# MSS_CPSW register map
Vendor: Texas Instruments
Peripheral module from a debugger description file (folder awr29xx).
Registers are 32-bit, read-write, no defined reset value unless marked. A register's access mark holds for its fields unless they carry their own. Offsets are as the file gives them; lines under a group give offsets from that group; [hi:lo] are bit positions; {n}, {i} and the like mark numbered series; 'fields as' and 'values as' point back to an identical list; <NAME> marks a mode.

## MSS_CPSW (part 1 of 3)
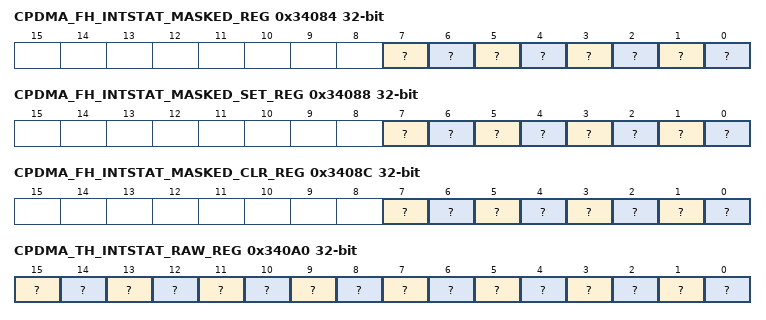
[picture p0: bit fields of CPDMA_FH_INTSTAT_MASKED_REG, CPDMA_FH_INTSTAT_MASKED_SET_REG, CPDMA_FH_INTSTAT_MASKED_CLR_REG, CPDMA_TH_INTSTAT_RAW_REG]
0x34084 CPDMA_FH_INTSTAT_MASKED_REG ro — CPDMA FHost Interrupt Status MASKED
  [7] ? — CPDMA FHost Channel 7 Interrupt Pending MASKED
  [6] ? — CPDMA FHost Channel 6 Interrupt Pending MASKED
  [5] ? — CPDMA FHost Channel 5 Interrupt Pending MASKED
  [4] ? — CPDMA FHost Channel 4 Interrupt Pending MASKED
  [3] ? — CPDMA FHost Channel 3 Interrupt Pending MASKED
  [2] ? — CPDMA FHost Channel 2 Interrupt Pending MASKED
  [1] ? — CPDMA FHost Channel 1 Interrupt Pending MASKED
  [0] ? — CPDMA FHost Channel 0 Interrupt Pending MASKED
0x34088 CPDMA_FH_INTSTAT_MASKED_SET_REG — CPDMA FHost Interrupt Masked SET
  [7] ? — CPDMA FHost Channel 7 Interrupt Pending MASKED Set
  [6] ? — CPDMA FHost Channel 6 Interrupt Pending MASKED Set
  [5] ? — CPDMA FHost Channel 5 Interrupt Pending MASKED Set
  [4] ? — CPDMA FHost Channel 4 Interrupt Pending MASKED Set
  [3] ? — CPDMA FHost Channel 3 Interrupt Pending MASKED Set
  [2] ? — CPDMA FHost Channel 2 Interrupt Pending MASKED Set
  [1] ? — CPDMA FHost Channel 1 Interrupt Pending MASKED Set
  [0] ? — CPDMA FHost Channel 0 Interrupt Pending MASKED Set
0x3408C CPDMA_FH_INTSTAT_MASKED_CLR_REG — CPDMA FHost Interrupt Masked CLR
  [7] ? — CPDMA FHost Channel 7 Interrupt Pending MASKED Clr
  [6] ? — CPDMA FHost Channel 6 Interrupt Pending MASKED Clr
  [5] ? — CPDMA FHost Channel 5 Interrupt Pending MASKED Clr
  [4] ? — CPDMA FHost Channel 4 Interrupt Pending MASKED Clr
  [3] ? — CPDMA FHost Channel 3 Interrupt Pending MASKED Clr
  [2] ? — CPDMA FHost Channel 2 Interrupt Pending MASKED Clr
  [1] ? — CPDMA FHost Channel 1 Interrupt Pending MASKED Clr
  [0] ? — CPDMA FHost Channel 0 Interrupt Pending MASKED Clr
0x34090 CPDMA_IN_VECTOR_REG ro — CPDMA DMA IN Vector
  [31:0] ?
0x34094 CPDMA_EOI_VECTOR_REG — CPDMA DMA EOI Vector
  [4:0] ?
0x340A0 CPDMA_TH_INTSTAT_RAW_REG ro — CPDMA Receive Interrupt Status RAW
  [15] ? — CPDMA Receive Channel 7 Threshold Interrupt Pending RAW
  [14] ? — CPDMA Receive Channel 6 Threshold Interrupt Pending RAW
  [13] ? — CPDMA Receive Channel 5 Threshold Interrupt Pending RAW
  [12] ? — CPDMA Receive Channel 4 Threshold Interrupt Pending RAW
  [11] ? — CPDMA Receive Channel 3 Threshold Interrupt Pending RAW
  [10] ? — CPDMA Receive Channel 2 Threshold Interrupt Pending RAW
  [9] ? — CPDMA Receive Channel 1 Threshold Interrupt Pending RAW
  [8] ? — CPDMA Receive Channel 0 Threshold Interrupt Pending RAW
  [7] ? — CPDMA Receive Channel 7 Interrupt Pending RAW
  [6] ? — CPDMA Receive Channel 6 Interrupt Pending RAW
  [5] ? — CPDMA Receive Channel 5 Interrupt Pending RAW
  [4] ? — CPDMA Receive Channel 4 Interrupt Pending RAW
  [3] ? — CPDMA Receive Channel 3 Interrupt Pending RAW
  [2] ? — CPDMA Receive Channel 2 Interrupt Pending RAW
  [1] ? — CPDMA Receive Channel 1 Interrupt Pending RAW
  [0] ? — CPDMA Receive Channel 0 Interrupt Pending RAW
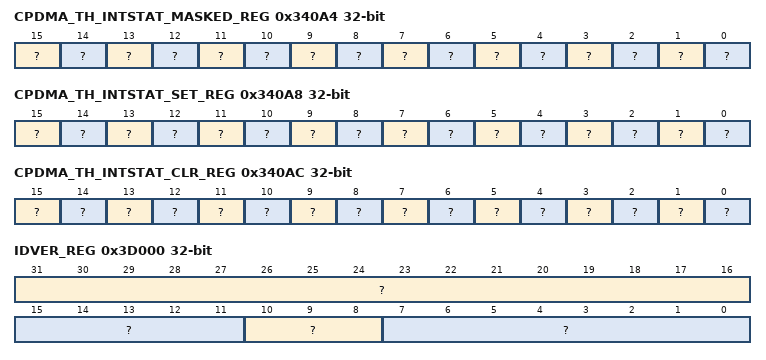
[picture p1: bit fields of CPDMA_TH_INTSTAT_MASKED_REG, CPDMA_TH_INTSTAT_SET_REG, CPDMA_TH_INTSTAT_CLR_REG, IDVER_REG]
0x340A4 CPDMA_TH_INTSTAT_MASKED_REG ro — CPDMA Receive Interrupt Status MASKED
  [15] ? — CPDMA Receive Channel 7 Threshold Interrupt Pending MASKED
  [14] ? — CPDMA Receive Channel 6 Threshold Interrupt Pending MASKED
  [13] ? — CPDMA Receive Channel 5 Threshold Interrupt Pending MASKED
  [12] ? — CPDMA Receive Channel 4 Threshold Interrupt Pending MASKED
  [11] ? — CPDMA Receive Channel 3 Threshold Interrupt Pending MASKED
  [10] ? — CPDMA Receive Channel 2 Threshold Interrupt Pending MASKED
  [9] ? — CPDMA Receive Channel 1 Threshold Interrupt Pending MASKED
  [8] ? — CPDMA Receive Channel 0 Threshold Interrupt Pending MASKED
  [7] ? — CPDMA Receive Channel 7 Interrupt Pending MASKED
  [6] ? — CPDMA Receive Channel 6 Interrupt Pending MASKED
  [5] ? — CPDMA Receive Channel 5 Interrupt Pending MASKED
  [4] ? — CPDMA Receive Channel 4 Interrupt Pending MASKED
  [3] ? — CPDMA Receive Channel 3 Interrupt Pending MASKED
  [2] ? — CPDMA Receive Channel 2 Interrupt Pending MASKED
  [1] ? — CPDMA Receive Channel 1 Interrupt Pending MASKED
  [0] ? — CPDMA Receive Channel 0 Interrupt Pending MASKED
0x340A8 CPDMA_TH_INTSTAT_SET_REG — CPDMA THost Interrupt Masked SET
  [15] ? — CPDMA THost Channel 7 Threshold Interrupt Pending SET
  [14] ? — CPDMA THost Channel 6 Threshold Interrupt Pending SET
  [13] ? — CPDMA THost Channel 5 Threshold Interrupt Pending SET
  [12] ? — CPDMA THost Channel 4 Threshold Interrupt Pending SET
  [11] ? — CPDMA THost Channel 3 Threshold Interrupt Pending SET
  [10] ? — CPDMA THost Channel 2 Threshold Interrupt Pending SET
  [9] ? — CPDMA THost Channel 1 Threshold Interrupt Pending SET
  [8] ? — CPDMA THost Channel 0 Threshold Interrupt Pending SET
  [7] ? — CPDMA THost Channel 7 Interrupt Pending SET
  [6] ? — CPDMA THost Channel 6 Interrupt Pending SET
  [5] ? — CPDMA THost Channel 5 Interrupt Pending SET
  [4] ? — CPDMA THost Channel 4 Interrupt Pending SET
  [3] ? — CPDMA THost Channel 3 Interrupt Pending SET
  [2] ? — CPDMA THost Channel 2 Interrupt Pending SET
  [1] ? — CPDMA THost Channel 1 Interrupt Pending SET
  [0] ? — CPDMA THost Channel 0 Interrupt Pending SET
0x340AC CPDMA_TH_INTSTAT_CLR_REG — CPDMA THost Interrupt Masked CLR
  [15] ? — CPDMA THost Channel 7 Threshold Interrupt Pending CLR
  [14] ? — CPDMA THost Channel 6 Threshold Interrupt Pending CLR
  [13] ? — CPDMA THost Channel 5 Threshold Interrupt Pending CLR
  [12] ? — CPDMA THost Channel 4 Threshold Interrupt Pending CLR
  [11] ? — CPDMA THost Channel 3 Threshold Interrupt Pending CLR
  [10] ? — CPDMA THost Channel 2 Threshold Interrupt Pending CLR
  [9] ? — CPDMA THost Channel 1 Threshold Interrupt Pending CLR
  [8] ? — CPDMA THost Channel 0 Threshold Interrupt Pending CLR
  [7] ? — CPDMA THost Channel 7 Interrupt Pending CLR
  [6] ? — CPDMA THost Channel 6 Interrupt Pending CLR
  [5] ? — CPDMA THost Channel 5 Interrupt Pending CLR
  [4] ? — CPDMA THost Channel 4 Interrupt Pending CLR
  [3] ? — CPDMA THost Channel 3 Interrupt Pending CLR
  [2] ? — CPDMA THost Channel 2 Interrupt Pending CLR
  [1] ? — CPDMA THost Channel 1 Interrupt Pending CLR
  [0] ? — CPDMA THost Channel 0 Interrupt Pending CLR
0x340B0 CPDMA_INTSTAT_RAW_REG ro — CPDMA DMA Interrupt Status RAW
  [1] ? — CPDMA HOST Interrupt Pending RAW
0x340B4 CPDMA_INTSTAT_MASKED_REG ro — CPDMA DMA Interrupt Status MASKED
  [1] ? — CPDMA HOST Interrupt Pending MASKED
0x340B8 CPDMA_INTSTAT_SET_REG — CPDMA DMA Interrupt Status SET
  [1] ? — CPDMA HOST Interrupt Masked SET
0x340BC CPDMA_INTSTAT_CLR_REG — CPDMA DMA Interrupt Status CLR
  [1] ? — CPDMA HOST Interrupt Masked CLR
{0x340C0+4i} CPDMA_TH{i}_PENDTHRESH_REG (i=0..7) — CPDMA THost Threshold Pending Register
  [7:0] ?
{0x340E0+4i} CPDMA_TH{i}_FREEBUFFER_REG (i=0..7) — CPDMA THost Free Buffer Count Register
  [14:0] ?
{0x34200+4i} CPDMA_FH{i}_HDP_REG (i=0..7) — CPDMA FHost Channel {i} Head Descriptor Pointer
  [31:0] ?
{0x34220+4i} CPDMA_TH{i}_HDP_REG (i=0..7) — CPDMA THost Channel {i} Head Descriptor Pointer
  [31:0] ?
{0x34240+4i} CPDMA_FH{i}_CP_REG (i=0..7) — CPDMA FHost Channel {i} Completion Pointer
  [31:0] ?
{0x34260+4i} CPDMA_TH{i}_CP_REG (i=0..7) — CPDMA THost Channel {i} Completion Pointer
  [31:0] ?
{0x34300+4i} TEST_CPDMA_FH{i}_HDP_REG (i=0..7) — Test CPDMA FHost Channel {i} Head Descriptor Pointer
  [31:0] ?
{0x34320+4i} TEST_CPDMA_TH{i}_HDP_REG (i=0..7) — Test CPDMA THost Channel {i} Head Descriptor Pointer
  [31:0] ?
{0x34340+4i} TEST_CPDMA_FH{i}_CP_REG (i=0..7) — Test CPDMA FHost Channel {i} Completion Pointer
  [31:0] ?
{0x34360+4i} TEST_CPDMA_TH{i}_CP_REG (i=0..7) — Test CPDMA THost Channel {i} Completion Pointer
  [31:0] ?
0x3A000 RXGOODFRAMES — Total number of good frames received
  [31:0] ?
0x3A004 RXBROADCASTFRAMES — Total number of good broadcast frames received
  [31:0] ?
0x3A008 RXMULTICASTFRAMES — Total number of good multicast frames received
  [31:0] ?
0x3A010 RXCRCERRORS — Total number of CRC errors frames received
  [31:0] ?
0x3A018 RXOVERSIZEDFRAMES — Total number of oversized frames received
  [31:0] ?
0x3A020 RXUNDERSIZEDFRAMES — Total number of undersized frames received
  [31:0] ?
0x3A024 RXFRAGMENTS — Total number of fragmented frames received
  [31:0] ?
0x3A028 ALE_DROP — Total number of frames dropped by the ALE
  [31:0] ?
0x3A02C ALE_OVERRUN_DROP — Total number of overrun frames dropped by the ALE
  [31:0] ?
0x3A030 RXOCTETS — Total number of received bytes in good frames
  [31:0] ?
0x3A034 TXGOODFRAMES — Total number of good frames transmitted
  [31:0] ?
0x3A038 TXBROADCASTFRAMES — Total number of good broadcast frames transmitted
  [31:0] ?
0x3A03C TXMULTICASTFRAMES — Total number of good multicast frames transmitted
  [31:0] ?
0x3A04C TXSINGLECOLLFRAMES — Total number of transmitted frames experiencing a single collision
  [31:0] ?
0x3A050 TXMULTCOLLFRAMES — Total number of transmitted frames experiencing multiple collisions
  [31:0] ?
0x3A064 TXOCTETS — Total number of bytes in all good frames transmitted
  [31:0] ?
0x3A068 OCTETFRAMES64 — Total number of 64-byte frames received and transmitted
  [31:0] ?
0x3A06C OCTETFRAMES65T127 — Total number of frames of size 65 to 127 bytes received and transmitted
  [31:0] ?
0x3A070 OCTETFRAMES128T255 — Total number of frames of size 128 to 255 bytes received and transmitted
  [31:0] ?
0x3A074 OCTETFRAMES256T511 — Total number of frames of size 256 to 511 bytes received and transmitted
  [31:0] ?
0x3A078 OCTETFRAMES512T1023 — Total number of frames of size 512 to 1023 bytes received and transmitted
  [31:0] ?
0x3A07C OCTETFRAMES1024TUP — Total number of frames of size 1024 to rx_maxlen bytes received and 1024 bytes or greater transmitted
  [31:0] ?
0x3A080 NETOCTETS — Total number of bytes received and transmitted
  [31:0] ?
0x3A084 RX_BOTTOM_OF_FIFO_DROP — Receive Bottom of FIFO Drop
  [31:0] ?
0x3A088 PORTMASK_DROP — Total number of dropped frames received due to portmask
  [31:0] ?
0x3A08C RX_TOP_OF_FIFO_DROP — Receive Top of FIFO Drop
  [31:0] ?
0x3A090 ALE_RATE_LIMIT_DROP — Total number of dropped frames due to ALE Rate Limiting
  [31:0] ?
0x3A094 ALE_VID_INGRESS_DROP — Total number of dropped frames due to ALE VID Ingress
  [31:0] ?
0x3A098 ALE_DA_EQ_SA_DROP — Total number of dropped frames due to DA=SA
  [31:0] ?
0x3A09C ALE_BLOCK_DROP — Total number of dropped frames due to ALE Block Mode
  [31:0] ?
0x3A0A0 ALE_SECURE_DROP — Total number of dropped frames due to ALE Secure Mode
  [31:0] ?
0x3A0A4 ALE_AUTH_DROP — Total number of dropped frames due to ALE Authentication
  [31:0] ?
0x3A0A8 ALE_UNKN_UNI — ALE Receive Unknown Unicast
  [31:0] ?
0x3A0AC ALE_UNKN_UNI_BCNT — ALE Receive Unknown Unicast Bytecount
  [31:0] ?
0x3A0B0 ALE_UNKN_MLT — ALE Receive Unknown Multicast
  [31:0] ?
0x3A0B4 ALE_UNKN_MLT_BCNT — ALE Receive Unknown Multicast Bytecount
  [31:0] ?
0x3A0B8 ALE_UNKN_BRD — ALE Receive Unknown Broadcast
  [31:0] ?
0x3A0BC ALE_UNKN_BRD_BCNT — ALE Receive Unknown Broadcast Bytecount
  [31:0] ?
0x3A0C0 ALE_POL_MATCH — ALE Policer Matched
  [31:0] ?
0x3A0C4 ALE_POL_MATCH_RED — ALE Policer Matched and Condition Red
  [31:0] ?
0x3A0C8 ALE_POL_MATCH_YELLOW — ALE Policer Matched and Condition Yellow
  [31:0] ?
0x3A0CC ALE_MULT_SA_DROP — ALE Multicast Source Address Drop
  [31:0] ? — ALE Multicast Source Address drop
0x3A0D0 ALE_DUAL_VLAN_DROP
  [31:0] ? — ALE Dual VLAN drop
0x3A0D4 ALE_LEN_ERROR_DROP — ALE Length Error Drop
  [31:0] ? — ALE Length Error drop
0x3A0D8 ALE_IP_NEXT_HDR_DROP — ALE IP Next Header Drop
  [31:0] ? — ALE Next Header drop
0x3A0DC ALE_IPV4_FRAG_DROP
  [31:0] ? — ALE IPV4 Fragment drop
0x3A17C TX_MEMORY_PROTECT_ERROR — Transmit Memory Protect CRC Error
  [7:0] ?
0x3A200 RXGOODFRAMES — Total number of good frames received
  [31:0] ?
0x3A204 RXBROADCASTFRAMES — Total number of good broadcast frames received
  [31:0] ?
0x3A208 RXMULTICASTFRAMES — Total number of good multicast frames received
  [31:0] ?
0x3A20C RXPAUSEFRAMES — Total number of pause frames received
  [31:0] ?
0x3A210 RXCRCERRORS — Total number of CRC errors frames received
  [31:0] ?
0x3A214 RXALIGNCODEERRORS — Total number of alignment/code errors received
  [31:0] ?
0x3A218 RXOVERSIZEDFRAMES — Total number of oversized frames received
  [31:0] ?
0x3A21C RXJABBERFRAMES — Total number of jabber frames received
  [31:0] ?
0x3A220 RXUNDERSIZEDFRAMES — Total number of undersized frames received
  [31:0] ?
0x3A224 RXFRAGMENTS — Total number of fragmented frames received
  [31:0] ?
0x3A228 ALE_DROP — Total number of frames dropped by the ALE
  [31:0] ?
0x3A22C ALE_OVERRUN_DROP — Total number of overrun frames dropped by the ALE
  [31:0] ?
0x3A230 RXOCTETS — Total number of received bytes in good frames
  [31:0] ?
0x3A234 TXGOODFRAMES — Total number of good frames transmitted
  [31:0] ?
0x3A238 TXBROADCASTFRAMES — Total number of good broadcast frames transmitted
  [31:0] ?
0x3A23C TXMULTICASTFRAMES — Total number of good multicast frames transmitted
  [31:0] ?
0x3A240 TXPAUSEFRAMES — Total number of pause frames transmitted
  [31:0] ?
0x3A244 TXDEFERREDFRAMES — Total number of deferred frames transmitted
  [31:0] ?
0x3A248 TXCOLLISIONFRAMES — Total number of transmitted frames experiencing a collision
  [31:0] ?
0x3A24C TXSINGLECOLLFRAMES — Total number of transmitted frames experiencing a single collision
  [31:0] ?
0x3A250 TXMULTCOLLFRAMES — Total number of transmitted frames experiencing multiple collisions
  [31:0] ?
0x3A254 TXEXCESSIVECOLLISIONS — Total number of transmitted frames abandoned due to excessive collisions
  [31:0] ?
0x3A258 TXLATECOLLISIONS — Total number of transmitted frames abandoned due to a late collision
  [31:0] ?
0x3A25C RXIPGERROR — Total number of receive inter-packet gap errors (10G only)
  [31:0] ?
0x3A260 TXCARRIERSENSEERRORS — Total number of transmitted frames that experienced a carrier loss
  [31:0] ?
0x3A264 TXOCTETS — Total number of bytes in all good frames transmitted
  [31:0] ?
0x3A268 OCTETFRAMES64 — Total number of 64-byte frames received and transmitted
  [31:0] ?
0x3A26C OCTETFRAMES65T127 — Total number of frames of size 65 to 127 bytes received and transmitted
  [31:0] ?
0x3A270 OCTETFRAMES128T255 — Total number of frames of size 128 to 255 bytes received and transmitted
  [31:0] ?
0x3A274 OCTETFRAMES256T511 — Total number of frames of size 256 to 511 bytes received and transmitted
  [31:0] ?
0x3A278 OCTETFRAMES512T1023 — Total number of frames of size 512 to 1023 bytes received and transmitted
  [31:0] ?
0x3A27C OCTETFRAMES1024TUP — Total number of frames of size 1024 to rx_maxlen bytes received and 1024 bytes or greater transmitted
  [31:0] ?
0x3A280 NETOCTETS — Total number of bytes received and transmitted
  [31:0] ?
0x3A284 RX_BOTTOM_OF_FIFO_DROP — Receive Bottom of FIFO Drop
  [31:0] ?
0x3A288 PORTMASK_DROP — Total number of dropped frames received due to portmask
  [31:0] ?
0x3A28C RX_TOP_OF_FIFO_DROP — Receive Top of FIFO Drop
  [31:0] ?
0x3A290 ALE_RATE_LIMIT_DROP — Total number of dropped frames due to ALE Rate Limiting
  [31:0] ?
0x3A294 ALE_VID_INGRESS_DROP — Total number of dropped frames due to ALE VID Ingress
  [31:0] ?
0x3A298 ALE_DA_EQ_SA_DROP — Total number of dropped frames due to DA=SA
  [31:0] ?
0x3A29C ALE_BLOCK_DROP — Total number of dropped frames due to ALE Block Mode
  [31:0] ?
0x3A2A0 ALE_SECURE_DROP — Total number of dropped frames due to ALE Secure Mode
  [31:0] ?
0x3A2A4 ALE_AUTH_DROP — Total number of dropped frames due to ALE Authentication
  [31:0] ?
0x3A2A8 ALE_UNKN_UNI — ALE Receive Unknown Unicast
  [31:0] ?
0x3A2AC ALE_UNKN_UNI_BCNT — ALE Receive Unknown Unicast Bytecount
  [31:0] ?
0x3A2B0 ALE_UNKN_MLT — ALE Receive Unknown Multicast
  [31:0] ?
0x3A2B4 ALE_UNKN_MLT_BCNT — ALE Receive Unknown Multicast Bytecount
  [31:0] ?
0x3A2B8 ALE_UNKN_BRD — ALE Receive Unknown Broadcast
  [31:0] ?
0x3A2BC ALE_UNKN_BRD_BCNT — ALE Receive Unknown Broadcast Bytecount
  [31:0] ?
0x3A2C0 ALE_POL_MATCH — ALE Policer Matched
  [31:0] ?
0x3A2C4 ALE_POL_MATCH_RED — ALE Policer Matched and Condition Red
  [31:0] ?
0x3A2C8 ALE_POL_MATCH_YELLOW — ALE Policer Matched and Condition Yellow
  [31:0] ?
0x3A2CC ALE_MULT_SA_DROP — ALE Multicast Source Address Drop
  [31:0] ? — ALE Multicast Source Address drop
0x3A2D0 ALE_DUAL_VLAN_DROP
  [31:0] ? — ALE Dual VLAN drop
0x3A2D4 ALE_LEN_ERROR_DROP — ALE Length Error Drop
  [31:0] ? — ALE Length Error drop
0x3A2D8 ALE_IP_NEXT_HDR_DROP — ALE IP Next Header Drop
  [31:0] ? — ALE Next Header drop
0x3A2DC ALE_IPV4_FRAG_DROP
  [31:0] ? — ALE IPV4 Fragment drop
0x3A37C TX_MEMORY_PROTECT_ERROR — Transmit Memory Protect CRC Error
  [7:0] ?
{0x3A380+4i} ENET_PN_TX_PRI_REG_{i} (i=0..7) — ENET Port n PRIORITY N Packet Count
  [31:0] ? — ENET TX Priority Packet Count
{0x3A3A0+4i} ENET_PN_TX_PRI_BCNT_REG_{i} (i=0..7) — ENET Port n PRIORITY N Packet Byte Count
  [31:0] ?
{0x3A3C0+4i} ENET_PN_TX_PRI_DROP_REG_{i} (i=0..7) — ENET Port n PRIORITY N Packet Drop Count
  [31:0] ?
{0x3A3E0+4i} ENET_PN_TX_PRI_DROP_BCNT_REG_{i} (i=0..7) — ENET Port n PRIORITY N Packet Drop Byte Count
  [31:0] ?
0x3D000 IDVER_REG ro — Identification and Version Register
  [31:16] ? — Identification value
  [15:11] ? — RTL version value
  [10:8] ? — Major version value
  [7:0] ? — Minor version value
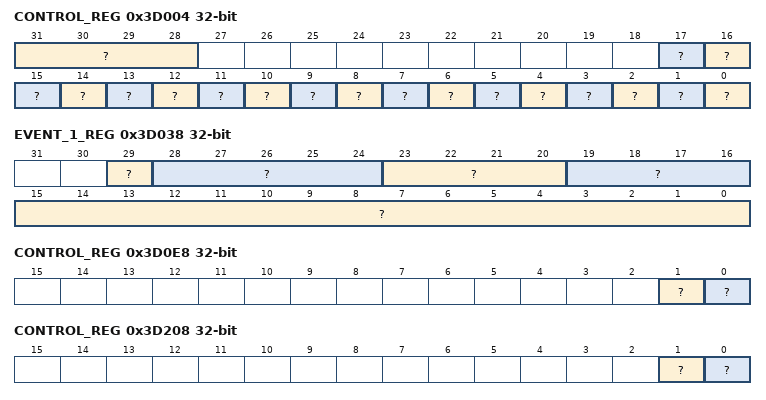
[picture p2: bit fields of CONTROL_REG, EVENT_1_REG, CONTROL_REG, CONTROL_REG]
0x3D004 CONTROL_REG — Time Sync Control Register
  [31:28] ? — TS_SYNC output timestamp counter bit select
  [17] ? — Enable for GENF clear when length is zero
  [16] ? — Receive Produces no Events
  [15] ? — Hardware push 8 enable
  [14] ? — Hardware push 7 enable
  [13] ? — Hardware push 6 enable
  [12] ? — Hardware push 5 enable
  [11] ? — Hardware push 4 enable
  [10] ? — Hardware push 3 enable
  [9] ? — Hardware push 2 enable
  [8] ? — Hardware push 1 enable
  [7] ? — Timestamp PPM Direction
  [6] ? — Timestamp Compare Toggle mode: 0=TS_COMP is in non-toggle mode, 1=TS_COMP is in toggle mode
  [5] ? — Timestamp mode
  [4] ? — Sequence Enable
  [3] ? — Host Receive Timestamp Enable
  [2] ? — TS_COMP polarity
  [1] ? — Interrupt test
  [0] ? — Time sync enable
0x3D008 RFTCLK_SEL_REG — RFTCLK Select Register
  [4:0] ? — Reference clock select
0x3D00C TS_PUSH_REG wo — Time Stamp Event Push Register
  [0] ? — Time stamp event push
0x3D010 TS_LOAD_VAL_REG — Time Stamp Load Low Value Register
  [31:0] ? — Time stamp load low value
0x3D014 TS_LOAD_EN_REG wo — Time Stamp Load Enable Register
  [0] ? — Time stamp load enable
0x3D018 TS_COMP_VAL_REG — Time Stamp Comparison Low Value Register
  [31:0] ? — Time stamp comparison low value
0x3D01C TS_COMP_LEN_REG — Time Stamp Comparison Length Register
  [31:0] ? — Time stamp comparison length
0x3D020 INTSTAT_RAW_REG — Interrupt Status Register Raw
  [0] ? — TS_PEND_RAW int read (before enable)
0x3D024 INTSTAT_MASKED_REG ro — Interrupt Status Register Masked
  [0] ? — TS_PEND masked interrupt read (after enable)
0x3D028 INT_ENABLE_REG — Interrupt Enable Register
  [0] ? — TS_PEND masked interrupt enable
0x3D02C TS_COMP_NUDGE_REG — Time Stamp Comparison Nudge Register
  [7:0] ? — This 2s complement number is added to the ts_comp_length value to increase or decrease the TS_COMP length by the nudge amount
0x3D030 EVENT_POP_REG wo — Event Pop Register
  [0] ? — Event pop
0x3D034 EVENT_0_REG ro — Event 0 Register
  [31:0] ? — Time Stamp
0x3D038 EVENT_1_REG ro — Event 1 Register
  [29] ? — Prempt QUEUE
  [28:24] ? — Port number
  [23:20] ? — Event type
  [19:16] ? — Message type
  [15:0] ? — Sequence ID
0x3D03C EVENT_2_REG ro — Event 2 Register
  [7:0] ? — Domain
0x3D040 EVENT_3_REG ro — Event 3 Register
  [31:0] ? — Time Stamp
0x3D044 TS_LOAD_HIGH_VAL_REG — Time Stamp Load High Value Register
  [31:0] ? — Time stamp load high value
0x3D048 TS_COMP_HIGH_VAL_REG — Time Stamp Comparison High Value Register
  [31:0] ? — Time stamp comparison high value
0x3D04C TS_ADD_VAL_REG — TS Add Value Register
  [2:0] ? — Add Value
0x3D050 TS_PPM_LOW_VAL_REG — Time Stamp PPM Low Value Register
  [31:0] ? — Time stamp PPM Low value
0x3D054 TS_PPM_HIGH_VAL_REG — Time Stamp PPM High Value Register
  [9:0] ? — Time stamp PPM High value
0x3D058 TS_NUDGE_VAL_REG — Time Stamp Nudge Value Register
  [7:0] ? — Time stamp Nudge value
0x3D0E0 COMP_LOW_REG — Time Stamp Generate Function Comparison Low Value
  [31:0] ?
0x3D0E4 COMP_HIGH_REG — Time Stamp Generate Function Comparison high Value
  [31:0] ? — Time Stamp Generate Function Comparison High Value
0x3D0E8 CONTROL_REG — Time Stamp Generate Function Control
  [1] ? — Time Stamp Generate Function Polarity Invert
  [0] ? — Time Stamp Generate Function PPM Direction
0x3D0EC LENGTH_REG — Time Stamp Generate Function Length Value
  [31:0] ?
0x3D0F0 PPM_LOW_REG — Time Stamp Generate Function PPM Low Value
  [31:0] ?
0x3D0F4 PPM_HIGH_REG — Time Stamp Generate Function PPM High Value
  [9:0] ?
0x3D0F8 NUDGE_REG — Time Stamp Generate Function Nudge Value
  [7:0] ?
0x3D200 COMP_LOW_REG — Time Stamp ESTF Generate Function Comparison Low Value
  [31:0] ?
0x3D204 COMP_HIGH_REG — Time Stamp ESTF Generate Function Comparison high Value
  [31:0] ? — Time Stamp ESTF Generate Function Comparison High Value
0x3D208 CONTROL_REG — Time Stamp ESTF Generate Function Control
  [1] ? — Time Stamp ESTF Generate Function Polarity Invert
  [0] ? — Time Stamp ESTF Generate Function PPM Direction
0x3D20C LENGTH_REG — Time Stamp ESTF Generate Function Length Value
  [31:0] ?
0x3D210 PPM_LOW_REG — Time Stamp ESTF Generate Function PPM Low Value
  [31:0] ?
0x3D214 PPM_HIGH_REG — Time Stamp ESTF Generate Function PPM High Value
  [9:0] ?
0x3D218 NUDGE_REG — Time Stamp ESTF Generate Function Nudge Value
  [7:0] ?
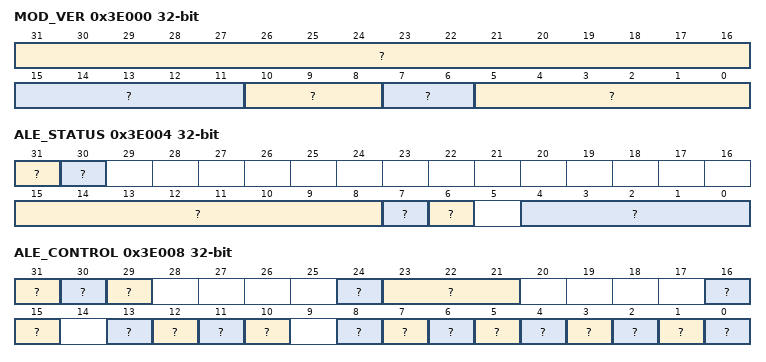
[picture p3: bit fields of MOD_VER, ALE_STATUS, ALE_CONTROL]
0x3E000 MOD_VER ro — The Module and Version Register identifies the module identifier and revision of the ALE_2g32 module.
  [31:16] ? — ALE_2g32 module ID.
  [15:11] ? — RTL Version.
  [10:8] ? — Major Revision.
  [7:6] ? — Custom Revision.
  [5:0] ? — Minor Revision.
0x3E004 ALE_STATUS ro — The ALE status provides information on the ALE configuration and state. The ~iramdepth is used to determine how IPv6 entries are stored in the table. IPv6 entries are stored in two entries where IPv6 Entry hi is designated by the odd slice index and lo is designated by the even slice index. The slice index is above the ram depth like {SlixeIndex,RamIndex}. So for a 64 deep RAM index of 0x005, the Hi portion of the IPv6 entry is located at 0x005|0x040 and the Lo portion is located at 0x005&(~0x040).
  [31] ? — When set, the unregistered multicast field is a mask versus an index on 12 bit boundary in the ALE table.
  [30] ? — When set, the unregistered multicast field is a mask versus an index on 8 bit boundary in the ALE table.
  [15:8] ? — This is the number of policer engines the ALE implements divided by 8. A value of 4 indicates 32 policer engines total.
  [7] ? — The number of ALE entries per slice of the table when this is set it indicates the depth is 128 if both ramdepth128 and ramdepth32 are zero the depth is 64.
  [6] ? — The number of ALE entries per slice of the table when this is set it indicates the depth is 32 if both ramdepth128 and ramdepth32 are zero the depth is 64.
  [4:0] ? — This is the number of table entries total divided by 1024. A value of 1 indicates 1024 table entries. A value of 8 indicates 8192 table entries.
0x3E008 ALE_CONTROL — The ALE Control Register is used to set the ALE modes used for all ports.
  [31] ? — Enable ALE#br# 0 - Drop all packets#br# 1 - Enable ALE packet processing
  [30] ? — Clear ALE address table - Setting this bit causes the ALE hardware to write all table bit values to zero. Software must perform a clear table operation as part of the ALE setup/configuration process. Setting this bit causes all ALE accesses to be held up for 64 clocks while the clear is performed. Access to all ALE registers will be blocked (wait states) until the 64 clocks have completed. This bit cannot be read as one because the read is blocked until the clear table is completed at which time this bit is cleared to zero.
  [29] ? — Age Out Address Table Now - Setting this bit causes the ALE hardware to remove (free up) any ageable table entry that does not have a set touch bit. This bit is cleared when the age out process has completed. This bit may be read. The age out process takes four times the number of table entries clock cycles (4096 cycles for 1K addresses) best case (no ale packet processing during ageout) and sixty five times the number of table entries clock cycles (66560 cycles for 1K addresses) absolute worst case.
  [24] ? — Mirror Destination Port - This field defines the port to which destination traffic destined will be duplicated. That is all traffic that is forwarded to this port will also be mirrored to the ~imirror_top port.
  [23:21] ? — The ~iupd_bw_ctrl field allows for up to 8 times the rate in which adds, updates, touches, writes, and aging updates can occur. At frequencies of 350Mhz, the table update rate should be at it lowest or 5 Million updates per second. When operating the switch core at frequencies or above, the ~iupd_bw_ctrl can be programmed more aggressive. If the ~iupd_bw_ctrl is set but the frequency of the switch subsystem is below the associated value, ALE will drop packets due to insufficient time to complete lookup under high traffic loads.#br# 0 - 350Mhz, 5M#br# 1 - 359Mhz, 11M#br# 2 - 367Mhz, 16M#br# 3 - 375Mhz, 22M#br# 4 - 384Mhz, 28M#br# 5 - 392Mhz, 34M#br# 6 - 400Mhz, 39M#br# 7 - 409Mhz, 45M
  [16] ? — Mirror To Port - This field defines the destination port for the mirror traffic. If the traffic is received or transmitted on the mirror destination port it will not be duplicated. Traffic defined as mirror traffic only may be dropped by the switch due to congestion.
  [15] ? — Update Static Entries - A static Entry is an entry that is not agable. When clear this bit will prevent any static entry (agable bit clear) from being updated due to port change. When set it allows static entries (agable bit clear) to update the source port if required. This bit should normally be '0' for most switch configurations.
  [13] ? — Unknown VLAN No Learn - This field when set will prevent source addresses of unknown VLAN IDs from being automatically added into the look up table if learning is enabled.
  [12] ? — Mirror Match Entry Enable - This field enables the match mirror option. When this bit is set any traffic whose destination, source, VLAN or OUI matches the ~imirror_midx entry index will have that traffic also sent to the ~imirror_top port.
  [11] ? — Mirror Destination Port Enable - This field enables the destination port mirror option. When this bit is set any traffic destined for the ~imirror_dp port will have its transmit traffic also sent to the ~imirror_top port.
  [10] ? — Mirror Source Port Enable - This field enables the source port mirror option. When this bit is set any port with the ~ipX_mirror_sp set in the ALE Port Control registers set will have its received traffic also sent to the ~imirror_top port.
  [8] ? — Unknown unicast packets flood to host#br# 0 - unknown unicast packets are not sent to the host#br# 1 - unknown unicast packets flood to host port as well as other ports
  [7] ? — Learn No VID -#br# 0 - VID is learned with the source address#br# 1 - VID is not learned with the source address (source address is not tied to VID). Determines the entry type.
  [6] ? — Enable VLAN ID = 0 Mode#br# 0 - Process the priority tagged packet with VID = PORT_VLAN[11:0].#br# 1 - Process the priority tagged packet with VID = 0.
  [5] ? — Enable OUI Deny Mode - When set, any packet with a non-matching OUI source address will be dropped to the host unless the packet destination address matches a supervisory destination address table entry. When cleared, any packet source address matching an OUI address table entry will be dropped to the host unless the destination address matches with a supervisory destination address table entry.
  [4] ? — ALE Bypass - When set, packets received on non-host ports are sent to the host. It is expected that packets from the host are directed to the particular port.#br# 0 - no bypass#br# 1 - bypass the ALE
  [3] ? — Rate Limit Transmit mode#br# 0 - Broadcast and multicast rate limit counters are received port based#br# 1 - Broadcast and multicast rate limit counters are transmit port based
  [2] ? — ALE VLAN Aware - Determines how traffic is forwarded using VLAN rules.#br# 0 - Simple switch rules, packets forwarded to all ports for unknown destinations.#br# 1 - VLAN Aware rules, packets forwarded based on VLAN members
  [1] ? — Enable MAC Authorization Mode - Mac authorization mode requires that all table entries be made by the host software. There is no auto learning of addresses in authorization mode and the packet will be dropped if the source address is not found (and the destination address is not a multicast address with the super table entry bit set).#br# 0 - The ALE is not in MAC authorization mode#br# 1 - The ALE is in MAC authorization mode
  [0] ? — Enable Broadcast and Multicast Rate Limit#br# 0 - Broadcast/Multicast rates not limited#br# 1 - Broadcast/Multicast packet reception limited to the port control register rate limit fields.
